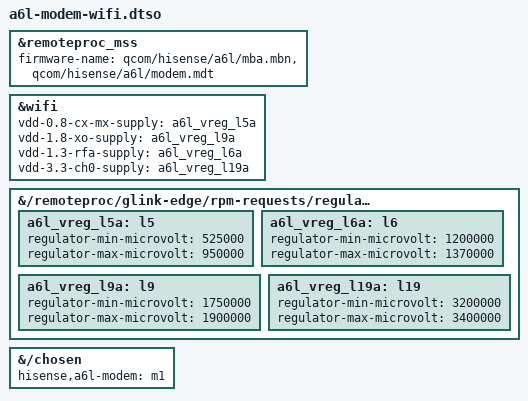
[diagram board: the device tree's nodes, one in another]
// SPDX-License-Identifier: GPL-2.0-only
// OFFLINE CANDIDATE "M1", never booted, NOT part of the V68 image. Modem + WCN3990 Wi-Fi enablement.
// Evidence: stock-00.dts icnss@18800000 supplies resolve to pm660 L5 (0.8 cx-mx), L9 pin-ctrl (1.8 xo),
// L6 pin-ctrl (1.3 rfa), L19 pin-ctrl (3.3 ch0) with the voltage windows copied below; identical to the
// mainline SDM660 reference boards. Reserved regions in the pinned sdm630.dtsi already equal stock
// (mpss 0x8ac00000/0x7e00000, mba 0x94800000/0x200000, wlan msa 0x85700000/0x100000, rmtfs 0x85e00000).
// Starting the modem is an RF-capable operation: attended only, antennas/SIM state decided by the user,
// rmtfs must serve RAM COPIES of modemst1/modemst2/fsg/fsc (never the live partitions).
/dts-v1/;
/plugin/;
&remoteproc_mss {
    firmware-name = "qcom/hisense/a6l/mba.mbn", "qcom/hisense/a6l/modem.mdt";
    status = "okay";
};
&wifi {
    vdd-0.8-cx-mx-supply = <&a6l_vreg_l5a>;
    vdd-1.8-xo-supply = <&a6l_vreg_l9a>;
    vdd-1.3-rfa-supply = <&a6l_vreg_l6a>;
    vdd-3.3-ch0-supply = <&a6l_vreg_l19a>;
    status = "okay";
};
/ {
    fragment@30 {
        target-path = "/remoteproc/glink-edge/rpm-requests/regulators-1";   // pm660 ("a") RPM regulators
        __overlay__ {
            a6l_vreg_l5a: l5 { regulator-min-microvolt = <525000>; regulator-max-microvolt = <950000>; };
            a6l_vreg_l6a: l6 { regulator-min-microvolt = <1200000>; regulator-max-microvolt = <1370000>; };
            a6l_vreg_l9a: l9 { regulator-min-microvolt = <1750000>; regulator-max-microvolt = <1900000>; };
            a6l_vreg_l19a: l19 { regulator-min-microvolt = <3200000>; regulator-max-microvolt = <3400000>; };
        };
    };
    fragment@31 {
        target-path = "/chosen";
        __overlay__ { hisense,a6l-modem = "m1"; };
    };
};
